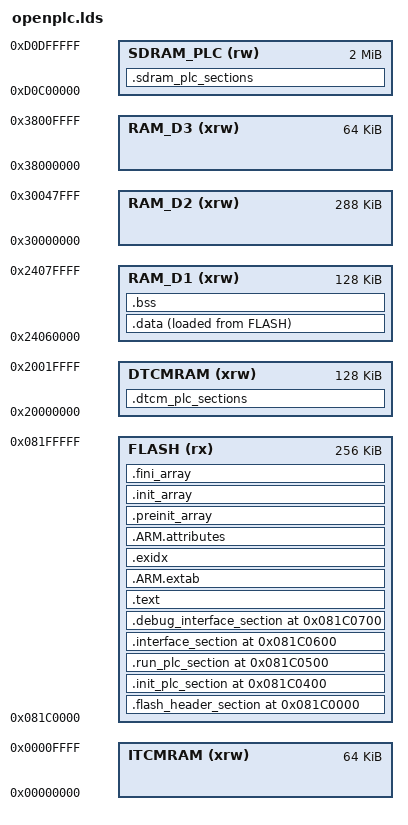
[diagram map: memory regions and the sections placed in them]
/* Generated by LinkerScriptGenerator [http://visualgdb.com/tools/LinkerScriptGenerator]
 * Target: STM32H747XI
 * The file is provided under the BSD license.
 */

/* ------------------------------------------------------------------ */
/* DEFINITION DER PUFFER-GRÖSSEN (in Bytes)                           */
/* Diese Werte sind "Variablen", die auch in C lesbar sind.           */
/* ------------------------------------------------------------------ */
_len_bool_in   = 0x2000;   /* 8KB für Bool Inputs */
_len_bool_out  = 0x2000;   /* 8KB für Bool Outputs */
_len_int_in    = 0x2000;   /* 8KB für Analog Inputs */
_len_int_out   = 0x2000;   /* 8KB für Analog Outputs */
_len_mem_int   = 0x8000;   /* 32KB für Memory Words */
_len_mem_dint  = 0x8000;   /* 32KB für Memory DWords */
_len_mem_lint  = 0x8000;   /* 32KB für Memory LWords */

MEMORY
{
	FLASH (rx)   : ORIGIN = 0x081C0000, LENGTH = 256K    /* Memory is divided. Actual start is 0x08000000 and actual length is 2048K */
	DTCMRAM (xrw)  : ORIGIN = 0x20000000, LENGTH = 128K
	RAM_D1 (xrw)   : ORIGIN = 0x24060000, LENGTH = 128K    
	RAM_D2 (xrw)   : ORIGIN = 0x30000000, LENGTH = 288K
	RAM_D3 (xrw)   : ORIGIN = 0x38000000, LENGTH = 64K
    SDRAM_PLC (rw) : ORIGIN = 0xD0C00000, LENGTH = 2M
	ITCMRAM (xrw)  : ORIGIN = 0x00000000, LENGTH = 64K
}


SECTIONS
{
    .flash_header_section 0x081C0000 : ALIGN(4)
    {
        KEEP(*(.flash_header_section))
    } > FLASH
 
    .init_plc_section 0x081C0400 : ALIGN(4)
    {
        KEEP(*(.init_plc_section))
    } > FLASH

    .run_plc_section 0x081C0500 : ALIGN(4)
    {
        KEEP(*(.run_plc_section))
    } > FLASH

    .interface_section 0x081C0600 : ALIGN(4)
    {
        KEEP(*(.interface_section))
    } > FLASH

    /* Optional versioned IEC debug ABI. Absent from production builds. */
    .debug_interface_section 0x081C0700 : ALIGN(4)
    {
        KEEP(*(.debug_interface_section))
    } > FLASH

	.text :
	{
		. = ALIGN(4);
		_stext = .;

		*(.text)
		*(.text*)
		*(.rodata)
		*(.rodata*)
		*(.glue_7)
		*(.glue_7t)
		KEEP(*(.init))
		KEEP(*(.fini))
		. = ALIGN(4);
		_etext = .;

	} > FLASH

	.ARM.extab :
	{
		. = ALIGN(4);
		*(.ARM.extab)
		*(.gnu.linkonce.armextab.*)
		. = ALIGN(4);
	} > FLASH

	.exidx :
	{
		. = ALIGN(4);
		PROVIDE(__exidx_start = .);
		*(.ARM.exidx*)
		. = ALIGN(4);
		PROVIDE(__exidx_end = .);
	} > FLASH

	.ARM.attributes :
	{
		*(.ARM.attributes)
	} > FLASH

	.preinit_array :
	{
		PROVIDE(__preinit_array_start = .);
		KEEP(*(.preinit_array*))
		PROVIDE(__preinit_array_end = .);
	} > FLASH

	.init_array :
	{
		PROVIDE(__init_array_start = .);
		KEEP(*(SORT(.init_array.*)))
		KEEP(*(.init_array*))
		PROVIDE(__init_array_end = .);
	} > FLASH

	.fini_array :
	{
		PROVIDE(__fini_array_start = .);
		KEEP(*(.fini_array*))
		KEEP(*(SORT(.fini_array.*)))
		PROVIDE(__fini_array_end = .);
	} > FLASH

	.data :
	{
		. = ALIGN(4);
		_sdata = .;

		PROVIDE(__data_start__ = _sdata);
		*(.data)
		*(.data*)
		. = ALIGN(4);
		_edata = .;

		PROVIDE(__data_end__ = _edata);
	} > RAM_D1 AT >FLASH

	_sidata = LOADADDR(.data);

	.bss :
	{
		. = ALIGN(4);
		_sbss = .;

		PROVIDE(__bss_start__ = _sbss);
		*(.bss)
		*(.bss*)
		*(COMMON)
		. = ALIGN(4);
		_ebss = .;

		PROVIDE(__bss_end__ = _ebss);
	} > RAM_D1

	PROVIDE(end = .);

    /* OpenPLC memory */
    .sdram_plc_sections (NOLOAD) :
    {
        /* Startadresse setzen (einmalig) */
        . = ABSOLUTE(0xD0C00000);

        /* --- 5. MEMORY WORDS --- */
        _start_mem_int = .;
        KEEP(*(.plc_mem_int))
        . = _start_mem_int + _len_mem_int;

        /* --- 6. MEMORY DWORDS --- */
        _start_mem_dint = .;
        KEEP(*(.plc_mem_dint))
        . = _start_mem_dint + _len_mem_dint;

        /* --- 7. MEMORY LWORDS --- */
        _start_mem_lint = .;
        KEEP(*(.plc_mem_lint))
        . = _start_mem_lint + _len_mem_lint;
    } > SDRAM_PLC

    /*OpenPLC I/O Pointers im extrem schnellen DTCM-RAM*/
    .dtcm_plc_sections (NOLOAD) :
    {
        . = ALIGN(4);

        /* --- Feste Startadresse für das SPS-Projekt im DTCM-RAM --- */
        . = ABSOLUTE(0x20010000);

        /* --- 1. BOOL INPUTS --- */
        _start_bool_in = .;
        KEEP(*(.plc_bool_in))
        . = _start_bool_in + _len_bool_in;

        /* --- 2. BOOL OUTPUTS --- */
        _start_bool_out = .;
        KEEP(*(.plc_bool_out))
        . = _start_bool_out + _len_bool_out;

        /* --- 3. INT INPUTS --- */
        _start_int_in = .;
        KEEP(*(.plc_int_in))
        . = _start_int_in + _len_int_in;

        /* --- 4. INT OUTPUTS --- */
        _start_int_out = .;
        KEEP(*(.plc_int_out))
        . = _start_int_out + _len_int_out;

        . = ALIGN(4);
    } > DTCMRAM
}
